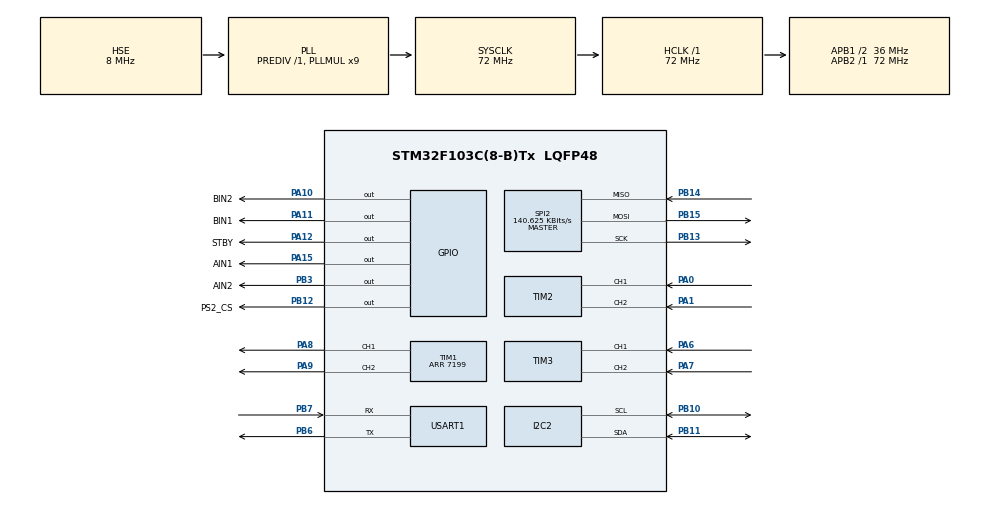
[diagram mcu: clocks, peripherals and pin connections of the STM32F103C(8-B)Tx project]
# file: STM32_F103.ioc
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Dma.Request0=USART1_TX
Dma.Request1=USART1_RX
Dma.USART1_RX.1.Direction=DMA_PERIPH_TO_MEMORY
Dma.USART1_RX.1.Instance=DMA1_Channel5
Dma.USART1_RX.1.MemDataAlignment=DMA_MDATAALIGN_BYTE
Dma.USART1_RX.1.MemInc=DMA_MINC_ENABLE
Dma.USART1_RX.1.Mode=DMA_CIRCULAR
Dma.USART1_RX.1.PeriphDataAlignment=DMA_PDATAALIGN_BYTE
Dma.USART1_RX.1.PeriphInc=DMA_PINC_DISABLE
Dma.USART1_RX.1.Priority=DMA_PRIORITY_MEDIUM
Dma.USART1_TX.0.Direction=DMA_MEMORY_TO_PERIPH
Dma.USART1_TX.0.Instance=DMA1_Channel4
Dma.USART1_TX.0.MemDataAlignment=DMA_MDATAALIGN_BYTE
Dma.USART1_TX.0.MemInc=DMA_MINC_ENABLE
Dma.USART1_TX.0.Mode=DMA_NORMAL
Dma.USART1_TX.0.PeriphDataAlignment=DMA_PDATAALIGN_BYTE
Dma.USART1_TX.0.PeriphInc=DMA_PINC_DISABLE
Dma.USART1_TX.0.Priority=DMA_PRIORITY_MEDIUM
FREERTOS.TOTAL_HEAP_SIZE=5120
FREERTOS.Tasks01=defaultTask,24,128,StartDefaultTask,Default,NULL,Dynamic,NULL,NULL;Move_Task,8,256,StartMoveTask,As external,NULL,Dynamic,NULL,NULL;RmoteTsk,8,128,StartRemoteTask,As external,NULL,Dynamic,NULL,NULL
Mcu.Family=STM32F1
Mcu.Name=STM32F103C(8-B)Tx
Mcu.Package=LQFP48
NVIC.DMA1_Channel4_IRQn=true\:5\:0\:false\:false\:true\:true\:false\:true\:true
NVIC.DMA1_Channel5_IRQn=true\:5\:0\:false\:false\:true\:true\:false\:true\:true
NVIC.PriorityGroup=NVIC_PRIORITYGROUP_4
NVIC.SPI2_IRQn=true\:5\:0\:false\:false\:true\:true\:true\:true\:true
NVIC.TIM1_UP_IRQn=true\:5\:0\:false\:false\:true\:true\:true\:true\:true
NVIC.TIM2_IRQn=true\:5\:0\:false\:false\:true\:true\:true\:true\:true
NVIC.TIM4_IRQn=true\:15\:0\:false\:false\:true\:false\:false\:true\:true
NVIC.TimeBase=TIM4_IRQn
NVIC.TimeBaseIP=TIM4
NVIC.USART1_IRQn=true\:5\:0\:false\:false\:true\:true\:true\:true\:true
PA0-WKUP.Signal=S_TIM2_CH1_ETR
PA1.Signal=S_TIM2_CH2
PA10.GPIO_Label=BIN2
PA10.Signal=GPIO_Output
PA11.GPIO_Label=BIN1
PA11.Signal=GPIO_Output
PA12.GPIO_Label=STBY
PA12.Signal=GPIO_Output
PA13.Mode=Serial_Wire
PA13.Signal=SYS_JTMS-SWDIO
PA14.Mode=Serial_Wire
PA14.Signal=SYS_JTCK-SWCLK
PA15.GPIO_Label=AIN1
PA15.Signal=GPIO_Output
PA6.Signal=S_TIM3_CH1
PA7.Signal=S_TIM3_CH2
PA8.Signal=S_TIM1_CH1
PA9.Signal=S_TIM1_CH2
PB10.Mode=I2C
PB10.Signal=I2C2_SCL
PB11.Mode=I2C
PB11.Signal=I2C2_SDA
PB12.GPIO_Label=PS2_CS
PB12.GPIO_PuPd=GPIO_NOPULL
PB12.PinState=GPIO_PIN_SET
PB12.Signal=GPIO_Output
PB13.Mode=Full_Duplex_Master
PB13.Signal=SPI2_SCK
PB14.GPIO_PuPd=GPIO_PULLUP
PB14.Mode=Full_Duplex_Master
PB14.Signal=SPI2_MISO
PB15.Mode=Full_Duplex_Master
PB15.Signal=SPI2_MOSI
PB3.GPIO_Label=AIN2
PB3.Signal=GPIO_Output
PB6.Mode=Asynchronous
PB6.Signal=USART1_TX
PB7.GPIO_PuPd=GPIO_PULLUP
PB7.Mode=Asynchronous
PB7.Signal=USART1_RX
PD0-OSC_IN.Mode=HSE-External-Oscillator
PD0-OSC_IN.Signal=RCC_OSC_IN
PD1-OSC_OUT.Mode=HSE-External-Oscillator
PD1-OSC_OUT.Signal=RCC_OSC_OUT
ProjectManager.HeapSize=0x200
ProjectManager.StackSize=0x400
ProjectManager.TargetToolchain=CMake
RCC.AHBFreq_Value=72000000
RCC.APB1CLKDivider=RCC_HCLK_DIV2
RCC.APB1Freq_Value=36000000
RCC.APB1TimFreq_Value=72000000
RCC.APB2Freq_Value=72000000
RCC.APB2TimFreq_Value=72000000
RCC.HCLKFreq_Value=72000000
RCC.PLLMUL=RCC_PLL_MUL9
RCC.PLLSourceVirtual=RCC_PLLSOURCE_HSE
RCC.SYSCLKFreq_VALUE=72000000
RCC.SYSCLKSource=RCC_SYSCLKSOURCE_PLLCLK
RCC.USBFreq_Value=72000000
SH.S_TIM1_CH1.0=TIM1_CH1,PWM Generation1 CH1
SH.S_TIM1_CH2.0=TIM1_CH2,PWM Generation2 CH2
SH.S_TIM2_CH1_ETR.0=TIM2_CH1,Encoder_Interface
SH.S_TIM2_CH2.0=TIM2_CH2,Encoder_Interface
SH.S_TIM3_CH1.0=TIM3_CH1,Encoder_Interface
SH.S_TIM3_CH2.0=TIM3_CH2,Encoder_Interface
SPI2.BaudRatePrescaler=SPI_BAUDRATEPRESCALER_256
SPI2.CLKPhase=SPI_PHASE_2EDGE
SPI2.CLKPolarity=SPI_POLARITY_HIGH
SPI2.CalculateBaudRate=140.625 KBits/s
SPI2.Direction=SPI_DIRECTION_2LINES
SPI2.FirstBit=SPI_FIRSTBIT_LSB
SPI2.Mode=SPI_MODE_MASTER
SPI2.VirtualType=VM_MASTER
TIM1.Channel-PWM\ Generation1\ CH1=TIM_CHANNEL_1
TIM1.Channel-PWM\ Generation2\ CH2=TIM_CHANNEL_2
TIM1.Period=7199
TIM2.EncoderMode=TIM_ENCODERMODE_TI12
TIM3.EncoderMode=TIM_ENCODERMODE_TI12
USART1.VirtualMode=VM_ASYNC
VP_FREERTOS_VS_CMSIS_V2.Mode=CMSIS_V2
VP_SYS_VS_tim4.Mode=TIM4
board=custom

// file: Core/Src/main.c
/* USER CODE BEGIN Header */
/**
  ******************************************************************************
  * @file           : main.c
  * @brief          : Main program body
  ******************************************************************************
  * @attention
  *
  * Copyright (c) 2026 STMicroelectronics.
  * All rights reserved.
  *
  * This software is licensed under terms that can be found in the LICENSE file
  * in the root directory of this software component.
  * If no LICENSE file comes with this software, it is provided AS-IS.
  *
  ******************************************************************************
  */
/* USER CODE END Header */
#include "main.h"
#include "cmsis_os.h"
#include "dma.h"
#include "i2c.h"
#include "spi.h"
#include "tim.h"
#include "usart.h"
#include "gpio.h"

/* USER CODE BEGIN Includes */
#include "app_move.h"
/* USER CODE END Includes */

void SystemClock_Config(void);
void MX_FREERTOS_Init(void);

int main(void)
{

  /* MCU Configuration--------------------------------------------------------*/

  /* Reset of all peripherals, Initializes the Flash interface and the Systick. */
  HAL_Init();

  /* Configure the system clock */
  SystemClock_Config();

  /* Initialize all configured peripherals */
  MX_GPIO_Init();
  MX_DMA_Init();
  MX_TIM1_Init();
  MX_TIM2_Init();
  MX_TIM3_Init();
  MX_SPI2_Init();
  MX_USART1_UART_Init();
  MX_I2C2_Init();

  /* Init scheduler */
  osKernelInitialize();  /* Call init function for freertos objects (in cmsis_os2.c) */
  MX_FREERTOS_Init();

  /* Start scheduler */
  osKernelStart();

  /* We should never get here as control is now taken by the scheduler */

  /* Infinite loop */
  while (1)
  {

  }
}

void SystemClock_Config(void)
{
  RCC_OscInitTypeDef RCC_OscInitStruct = {0};
  RCC_ClkInitTypeDef RCC_ClkInitStruct = {0};

  /** Initializes the RCC Oscillators according to the specified parameters
  * in the RCC_OscInitTypeDef structure.
  */
  RCC_OscInitStruct.OscillatorType = RCC_OSCILLATORTYPE_HSE;
  RCC_OscInitStruct.HSEState = RCC_HSE_ON;
  RCC_OscInitStruct.HSEPredivValue = RCC_HSE_PREDIV_DIV1;
  RCC_OscInitStruct.HSIState = RCC_HSI_ON;
  RCC_OscInitStruct.PLL.PLLState = RCC_PLL_ON;
  RCC_OscInitStruct.PLL.PLLSource = RCC_PLLSOURCE_HSE;
  RCC_OscInitStruct.PLL.PLLMUL = RCC_PLL_MUL9;
  if (HAL_RCC_OscConfig(&RCC_OscInitStruct) != HAL_OK)
  {
    Error_Handler();
  }

  /** Initializes the CPU, AHB and APB buses clocks
  */
  RCC_ClkInitStruct.ClockType = RCC_CLOCKTYPE_HCLK|RCC_CLOCKTYPE_SYSCLK
                              |RCC_CLOCKTYPE_PCLK1|RCC_CLOCKTYPE_PCLK2;
  RCC_ClkInitStruct.SYSCLKSource = RCC_SYSCLKSOURCE_PLLCLK;
  RCC_ClkInitStruct.AHBCLKDivider = RCC_SYSCLK_DIV1;
  RCC_ClkInitStruct.APB1CLKDivider = RCC_HCLK_DIV2;
  RCC_ClkInitStruct.APB2CLKDivider = RCC_HCLK_DIV1;

  if (HAL_RCC_ClockConfig(&RCC_ClkInitStruct, FLASH_LATENCY_2) != HAL_OK)
  {
    Error_Handler();
  }
}

void HAL_TIM_PeriodElapsedCallback(TIM_HandleTypeDef *htim)
{
  if (htim->Instance == TIM4)
  {
    HAL_IncTick();
  }
  /* USER CODE BEGIN Callback 1 */
  App_Move_TimerElapsedCallback(htim);
  /* USER CODE END Callback 1 */
}

void Error_Handler(void)
{
  __disable_irq();
  while (1)
  {
  }
}

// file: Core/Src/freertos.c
/* USER CODE BEGIN Header */
/**
  ******************************************************************************
  * File Name          : freertos.c
  * Description        : Code for freertos applications
  ******************************************************************************
  * @attention
  *
  * Copyright (c) 2026 STMicroelectronics.
  * All rights reserved.
  *
  * This software is licensed under terms that can be found in the LICENSE file
  * in the root directory of this software component.
  * If no LICENSE file comes with this software, it is provided AS-IS.
  *
  ******************************************************************************
  */
/* USER CODE END Header */

#include "FreeRTOS.h"
#include "task.h"
#include "main.h"
#include "cmsis_os.h"

/* USER CODE BEGIN Includes */
#include "app_host_comm.h"

/* USER CODE END Includes */

/* Definitions for defaultTask */
osThreadId_t defaultTaskHandle;
const osThreadAttr_t defaultTask_attributes = {
  .name = "defaultTask",
  .stack_size = 128 * 4,
  .priority = (osPriority_t) osPriorityNormal,
};
/* Definitions for Move_Task */
osThreadId_t Move_TaskHandle;
const osThreadAttr_t Move_Task_attributes = {
  .name = "Move_Task",
  .stack_size = 256 * 4,
  .priority = (osPriority_t) osPriorityLow,
};
/* Definitions for RmoteTsk */
osThreadId_t RmoteTskHandle;
const osThreadAttr_t RmoteTsk_attributes = {
  .name = "RmoteTsk",
  .stack_size = 128 * 4,
  .priority = (osPriority_t) osPriorityLow,
};

void StartDefaultTask(void *argument);
extern void StartMoveTask(void *argument);
extern void StartRemoteTask(void *argument);

void MX_FREERTOS_Init(void); /* (MISRA C 2004 rule 8.1) */

void MX_FREERTOS_Init(void) {

  /* Create the thread(s) */
  /* creation of defaultTask */
  defaultTaskHandle = osThreadNew(StartDefaultTask, NULL, &defaultTask_attributes);

  /* creation of Move_Task */
  Move_TaskHandle = osThreadNew(StartMoveTask, NULL, &Move_Task_attributes);

  /* creation of RmoteTsk */
  RmoteTskHandle = osThreadNew(StartRemoteTask, NULL, &RmoteTsk_attributes);

}

void StartDefaultTask(void *argument)
{
  /* USER CODE BEGIN StartDefaultTask */
  App_HostComm_Init();
  /* Infinite loop */
  for(;;)
  {
    App_HostComm_Poll();
    osDelay(1);
  }
  /* USER CODE END StartDefaultTask */
}
